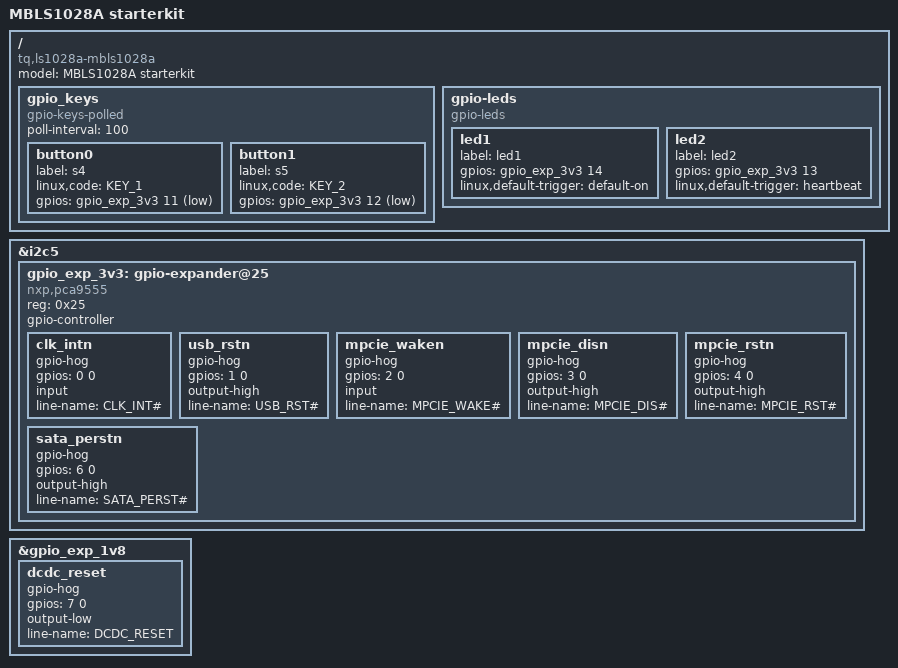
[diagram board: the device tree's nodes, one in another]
// SPDX-License-Identifier: (GPL-2.0-or-later OR MIT)
/*
 * Device Tree file for MBLS1028A starterkit
 *
 * Copyright 2019-2020 TQ-Systems GmbH
 *
 * Authors: Michael Krummsdorf <michael.krummsdorf@tq-group.com>
 *          Matthias Schiffer <matthias.schiffer@tq-group.com>
 */

/dts-v1/;

#include "fsl-ls1028a-mbls1028a.dtsi"
#include <dt-bindings/input/input.h>

/ {
	model = "MBLS1028A starterkit";
	compatible = "tq,ls1028a-mbls1028a", "tq,ls1028a-tqmls1028a", "fsl,ls1028a";

	gpio_keys {
		compatible = "gpio-keys-polled";
		poll-interval = <100>;

		button0 {
			label = "s4";
			linux,code = <KEY_1>;
			gpios = <&gpio_exp_3v3 11 GPIO_ACTIVE_LOW>;
		};

		button1 {
			label = "s5";
			linux,code = <KEY_2>;
			gpios = <&gpio_exp_3v3 12 GPIO_ACTIVE_LOW>;
		};
	};

	gpio-leds {
		compatible = "gpio-leds";

		led1 {
			label = "led1";
			gpios = <&gpio_exp_3v3 14 GPIO_ACTIVE_HIGH>;
			linux,default-trigger = "default-on";
		};

		led2 {
			label = "led2";
			gpios = <&gpio_exp_3v3 13 GPIO_ACTIVE_HIGH>;
			linux,default-trigger = "heartbeat";
		};
	};
};

&i2c5 {
	gpio_exp_3v3: gpio-expander@25 {
		compatible = "nxp,pca9555";
		reg = <0x25>;
		gpio-controller;
		#gpio-cells = <2>;

		clk_intn {
			gpio-hog;
			gpios = <0 0>;
			input;
			line-name = "CLK_INT#";
		};

		usb_rstn {
			gpio-hog;
			gpios = <1 0>;
			output-high;
			line-name = "USB_RST#";
		};

		mpcie_waken {
			gpio-hog;
			gpios = <2 0>;
			input;
			line-name = "MPCIE_WAKE#";
		};

		mpcie_disn {
			gpio-hog;
			gpios = <3 0>;
			output-high;
			line-name = "MPCIE_DIS#";
		};

		mpcie_rstn {
			gpio-hog;
			gpios = <4 0>;
			output-high;
			line-name = "MPCIE_RST#";
		};

		sata_perstn {
			gpio-hog;
			gpios = <6 0>;
			output-high;
			line-name = "SATA_PERST#";
		};
	};
};

&gpio_exp_1v8 {
	dcdc_reset {
		gpio-hog;
		gpios = <7 0>;
		output-low;
		line-name = "DCDC_RESET";
	};
};
